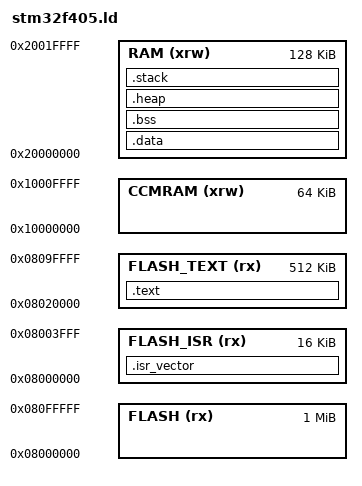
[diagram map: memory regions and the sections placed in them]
/*
    GNU linker script for STM32F405
*/

/* Specify the memory areas */
MEMORY
{
    FLASH (rx)      : ORIGIN = 0x08000000, LENGTH = 0x100000 /* entire flash, 1 MiB */
    FLASH_ISR (rx)  : ORIGIN = 0x08000000, LENGTH = 0x004000 /* sector 0, 16 KiB */
    FLASH_TEXT (rx) : ORIGIN = 0x08020000, LENGTH = 0x080000 /* sectors 5,6,7,8, 4*128KiB = 512 KiB (could increase it more) */
    CCMRAM (xrw)    : ORIGIN = 0x10000000, LENGTH = 0x010000 /* 64 KiB */
    RAM (xrw)       : ORIGIN = 0x20000000, LENGTH = 0x020000 /* 128 KiB */
}
 
/* top end of the stack */
_estack = ORIGIN(RAM) + LENGTH(RAM);

/* RAM extents for the garbage collector */
_ram_end = ORIGIN(RAM) + LENGTH(RAM);
_heap_end = 0x2001c000; /* tunable */

/* define output sections */
SECTIONS
{
    /* The startup code goes first into FLASH */
    .isr_vector :
    {
        . = ALIGN(4);
        KEEP(*(.isr_vector)) /* Startup code */

        . = ALIGN(4);
    } >FLASH_ISR
   
    /* The program code and other data goes into FLASH */
    .text :
    {
        . = ALIGN(4);
        *(.text)           /* .text sections (code) */
        *(.text*)          /* .text* sections (code) */
        *(.rodata)         /* .rodata sections (constants, strings, etc.) */
        *(.rodata*)        /* .rodata* sections (constants, strings, etc.) */
    /*  *(.glue_7)   */    /* glue arm to thumb code */
    /*  *(.glue_7t)  */    /* glue thumb to arm code */

        . = ALIGN(4);
        _etext = .;        /* define a global symbol at end of code */
        _sidata = _etext;  /* This is used by the startup in order to initialize the .data secion */
    } >FLASH_TEXT
     
    /*
    .ARM.extab :
    {
        *(.ARM.extab* .gnu.linkonce.armextab.*)
    } >FLASH

    .ARM :
    {
        __exidx_start = .;
        *(.ARM.exidx*)
        __exidx_end = .;
    } >FLASH
    */
        
    /* This is the initialized data section
    The program executes knowing that the data is in the RAM
    but the loader puts the initial values in the FLASH (inidata).
    It is one task of the startup to copy the initial values from FLASH to RAM. */
    .data : AT ( _sidata )
    {
        . = ALIGN(4);
        _sdata = .;        /* create a global symbol at data start; used by startup code in order to initialise the .data section in RAM */
        _ram_start = .;    /* create a global symbol at ram start for garbage collector */
        *(.data)           /* .data sections */
        *(.data*)          /* .data* sections */

        . = ALIGN(4);
        _edata = .;        /* define a global symbol at data end; used by startup code in order to initialise the .data section in RAM */
    } >RAM
            
    /* Uninitialized data section */
    .bss :
    {
        . = ALIGN(4);
        _sbss = .;         /* define a global symbol at bss start; used by startup code */
        *(.bss)
        *(.bss*)
        *(COMMON)

        . = ALIGN(4);
        _ebss = .;         /* define a global symbol at bss end; used by startup code */
    } >RAM

    /* this is to define the start of the heap, and make sure we have a minimum size */
    .heap :
    {
        . = ALIGN(4);
        _heap_start = .;    /* define a global symbol at heap start */
    } >RAM

    /* this just checks there is enough RAM for the stack */
    .stack :
    {
        . = ALIGN(4);
    } >RAM

    /* Remove information from the standard libraries */
    /*
    /DISCARD/ :
    {
        libc.a ( * )
        libm.a ( * )
        libgcc.a ( * )
    }
    */

    .ARM.attributes 0 : { *(.ARM.attributes) }
}
